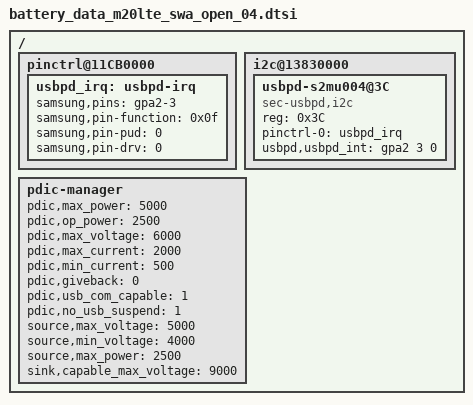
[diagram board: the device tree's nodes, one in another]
/*
 * SAMSUNG UNIVERSAL7885 board device tree source
 *
 * Copyright (c) 2013 Samsung Electronics Co., Ltd.
 *		http://www.samsung.com
 *
 * This program is free software; you can redistribute it and/or modify
 * it under the terms of the GNU General Public License version 2 as
 * published by the Free Software Foundation.
 */

/ {
	pinctrl@11CB0000 {
		usbpd_irq: usbpd-irq {
			samsung,pins = "gpa2-3";
			samsung,pin-function = <0x0f>;
			samsung,pin-pud = <0>;
			samsung,pin-drv = <0>;
		};
	};

	i2c@13830000 {
		usbpd-s2mu004@3C {
			compatible = "sec-usbpd,i2c";
			reg = <0x3C>;
			pinctrl-names = "default";
			pinctrl-0     = <&usbpd_irq>;
			usbpd,usbpd_int = <&gpa2 3 0>;
		};
	};

	pdic-manager {
		/* sink */
		pdic,max_power = <5000>;
		pdic,op_power = <2500>;
		pdic,max_voltage = <6000>;
		pdic,max_current = <2000>;
		pdic,min_current = <500>;

		pdic,giveback = <0>;
		pdic,usb_com_capable = <1>;
		pdic,no_usb_suspend = <1>;

		/* source */
		source,max_voltage = <5000>;
		source,min_voltage = <4000>;
		source,max_power = <2500>;

		/* sink cap */
		sink,capable_max_voltage = <9000>;
	};
};
